# RZT2H register map
Vendor: Renesas Electronics Corporation; Series: RZT; File version: 1.00.00
CPU: other r0p0, little endian, MPU, no FPU, VTOR, 4 interrupt priority bits, 624 interrupts
Registers are 32-bit, read-write, reset 0x0 unless marked. A register's access mark holds for its fields unless they carry their own. Offsets are from the block's base; [hi:lo] are bit positions; {n}, {i} and the like mark numbered series.

## MSAC — Master and Slave Access Control
Base 0x81290300
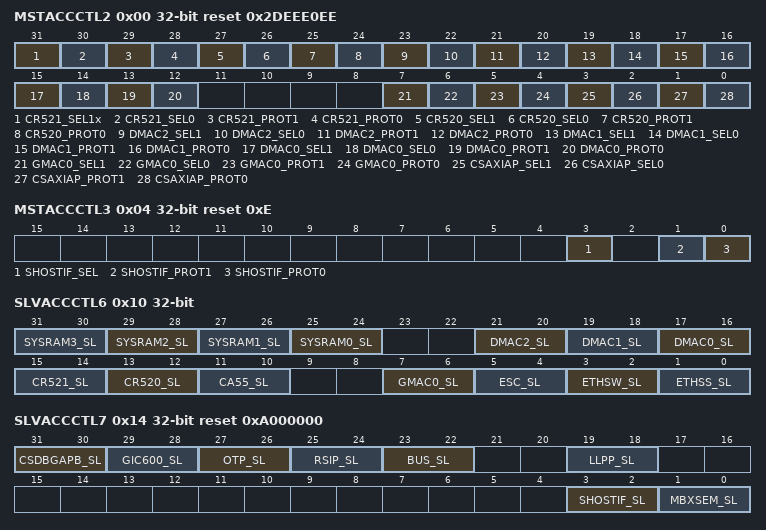
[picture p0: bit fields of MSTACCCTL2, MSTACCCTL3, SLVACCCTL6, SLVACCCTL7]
0x00 MSTACCCTL2 reset 0x2DEEE0EE — Master Access Control Register 2
  [31] CR521_SEL1x — CR521 Security Attribute (AxPROT[1]) Overwrite Select
    0=No overwrite; 1=Overwritten by CR521_PROT1
  [30] CR521_SEL0 — CR521 Privilege Attribute (AxPROT[0]) Overwrite Select
    0=No overwrite; 1=Overwritten by CR521_PROT0
  [29] CR521_PROT1 — CR521 Security Attribute Overwrite
    0=Secure; 1=Non-Secure
  [28] CR521_PROT0 — CR521 Privilege Attribute Overwrite
    0=Unprivileged; 1=Privileged
  [27] CR520_SEL1 — CR520 Security Attribute (AxPROT[1]) Overwrite Select
    0=No overwrite; 1=Overwritten by CR520_PROT1
  [26] CR520_SEL0 — CR520 Privilege Attribute (AxPROT[0]) Overwrite Select
    0=No overwrite; 1=Overwritten by CR520_PROT0
  [25] CR520_PROT1 — CR520 Security Attribute Overwrite
    0=Secure; 1=Non-Secure
  [24] CR520_PROT0 — CR520 Privilege Attribute Overwrite
    0=Unprivileged; 1=Privileged
  [23] DMAC2_SEL1 — DMAC2 Security Attribute (AxPROT[1]) Overwrite Select
    0=No overwrite; 1=Overwritten by DMAC2_PROT1
  [22] DMAC2_SEL0 — DMAC2 Privilege Attribute (AxPROT[0]) Overwrite Select
    0=No overwrite; 1=Overwritten by DMAC2_PROT0
  [21] DMAC2_PROT1 — DMAC2 Security Attribute Overwrite
    0=Secure; 1=Non-Secure
  [20] DMAC2_PROT0 — DMAC2 Privilege Attribute Overwrite
    0=Unprivileged; 1=Privileged
  [19] DMAC1_SEL1 — DMAC1 Security Attribute (AxPROT[1]) Overwrite Select
    0=No overwrite; 1=Overwritten by DMAC1_PROT1
  [18] DMAC1_SEL0 — DMAC1 Privilege Attribute (AxPROT[0]) Overwrite Select
    0=No overwrite; 1=Overwritten by DMAC1_PROT0
  [17] DMAC1_PROT1 — DMAC1 Security Attribute Overwrite
    0=Secure; 1=Non-Secure
  [16] DMAC1_PROT0 — DMAC1 Privilege Attribute Overwrite
    0=Unprivileged; 1=Privileged
  [15] DMAC0_SEL1 — DMAC0 Security Attribute (AxPROT[1]) Overwrite Select
    0=No overwrite; 1=Overwritten by DMAC0_PROT1
  [14] DMAC0_SEL0 — DMAC0 Privilege Attribute (AxPROT[0]) Overwrite Select
    0=No overwrite; 1=Overwritten by DMAC0_PROT0
  [13] DMAC0_PROT1 — DMAC0 Security Attribute Overwrite
    0=Secure; 1=Non-Secure
  [12] DMAC0_PROT0 — DMAC0 Privilege Attribute Overwrite
    0=Unprivileged; 1=Privileged
  [7] GMAC0_SEL1 — GMAC0 Security Attribute (AxPROT[1]) Overwrite Select
    0=No overwrite; 1=Overwritten by GMAC0_PROT1
  [6] GMAC0_SEL0 — GMAC0 Privilege Attribute (AxPROT[0]) Overwrite Select
    0=No overwrite; 1=Overwritten by GMAC0_PROT0
  [5] GMAC0_PROT1 — GMAC0 Security Attribute Overwrite
    0=Secure; 1=Non-Secure
  [4] GMAC0_PROT0 — GMAC0 Privilege Attribute Overwrite
    0=Unprivileged; 1=Privileged
  [3] CSAXIAP_SEL1 — CS AXI-AP Security Attribute (AxPROT[1]) Overwrite Select
    0=No overwrite; 1=Overwritten by CSAXIAP_PROT1
  [2] CSAXIAP_SEL0 — CS AXI-AP Privilege Attribute (AxPROT[0]) Overwrite Select
    0=No overwrite; 1=Overwritten by CSAXIAP_PROT0
  [1] CSAXIAP_PROT1 — CS AXI-AP Security Attribute Overwrite
    0=Secure; 1=Non-Secure
  [0] CSAXIAP_PROT0 — CS AXI-AP Privilege Attribute Overwrite
    0=Unprivileged; 1=Privileged
0x04 MSTACCCTL3 reset 0xE — Master Access Control Register 3
  [3] SHOSTIF_SEL — SHOSTIF Security Attribute (HNONSEC) and Privilege Attribute (HPROT[1]) Overwrite Select
    0=No overwrite; 1=Overwritten by SHOSTIF_PROT[1:0]
  [1] SHOSTIF_PROT1 — SHOSTIF Security Attribute Overwrite
    0=Secure; 1=Non-Secure
  [0] SHOSTIF_PROT0 — SHOSTIF Privilege Attribute Overwrite
    0=Unprivileged; 1=Privileged
0x10 SLVACCCTL6 — Slave Access Control Register 6
  [2n+25:2n+24] SYSRAM{n}_SL (n=0..3), [21:20] DMAC2_SL, [19:18] DMAC1_SL, [17:16] DMAC0_SL, [15:14] CR521_SL, [13:12] CR520_SL, [11:10] CA55_SL, [7:6] GMAC0_SL, [5:4] ESC_SL, [3:2] ETHSW_SL, [1:0] ETHSS_SL
0x14 SLVACCCTL7 reset 0xA000000 — Slave Access Control Register 7
  [31:30] CSDBGAPB_SL
  [29:28] GIC600_SL
  [27:26] OTP_SL
  [25:24] RSIP_SL
  [23:22] BUS_SL — Bus Security Level
  [19:18] LLPP_SL
  [3:2] SHOSTIF_SL
  [1:0] MBXSEM_SL
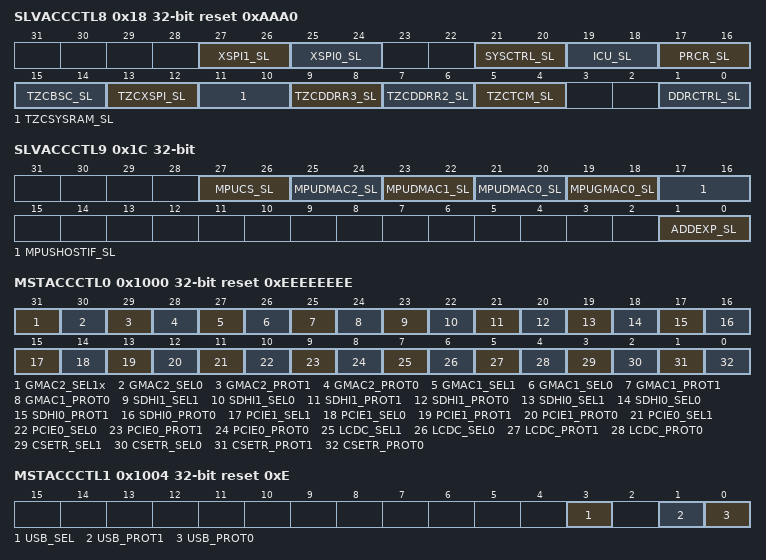
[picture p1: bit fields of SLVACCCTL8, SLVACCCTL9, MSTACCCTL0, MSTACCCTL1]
0x18 SLVACCCTL8 reset 0xAAA0 — Slave Access Control Register 8
  [27:26] XSPI1_SL, [25:24] XSPI0_SL, [21:20] SYSCTRL_SL, [19:18] ICU_SL, [17:16] PRCR_SL, [15:14] TZCBSC_SL, [13:12] TZCXSPI_SL, [11:10] TZCSYSRAM_SL, [9:8] TZCDDRR3_SL, [7:6] TZCDDRR2_SL, [5:4] TZCTCM_SL, [1:0] DDRCTRL_SL
0x1C SLVACCCTL9 — Slave Access Control Register 9
  [27:26] MPUCS_SL, [25:24] MPUDMAC2_SL, [23:22] MPUDMAC1_SL, [21:20] MPUDMAC0_SL, [19:18] MPUGMAC0_SL, [17:16] MPUSHOSTIF_SL, [1:0] ADDEXP_SL
0x1000 MSTACCCTL0 reset 0xEEEEEEEE — Master Access Control Register 0
  [31] GMAC2_SEL1x
    0=No overwrite; 1=Overwritten by GMAC2_PROT1
  [30] GMAC2_SEL0
    0=No overwrite; 1=Overwritten by GMAC2_PROT0
  [29] GMAC2_PROT1
    0=Secure; 1=Non-Secure
  [28] GMAC2_PROT0
    0=Unprivileged; 1=Privileged
  [27] GMAC1_SEL1
    0=No overwrite; 1=Overwritten by GMAC1_PROT1
  [26] GMAC1_SEL0
    0=No overwrite; 1=Overwritten by GMAC1_PROT0
  [25] GMAC1_PROT1
    0=Secure; 1=Non-Secure
  [24] GMAC1_PROT0
    0=Unprivileged; 1=Privileged
  [23] SDHI1_SEL1
    0=No overwrite; 1=Overwritten by SDHI1_PROT1
  [22] SDHI1_SEL0
    0=No overwrite; 1=Overwritten by SDHI1_PROT0
  [21] SDHI1_PROT1
    0=Secure; 1=Non-Secure
  [20] SDHI1_PROT0
    0=Unprivileged; 1=Privileged
  [19] SDHI0_SEL1
    0=No overwrite; 1=Overwritten by SDHI0_PROT1
  [18] SDHI0_SEL0
    0=No overwrite; 1=Overwritten by SDHI0_PROT0
  [17] SDHI0_PROT1
    0=Secure; 1=Non-Secure
  [16] SDHI0_PROT0
    0=Unprivileged; 1=Privileged
  [15] PCIE1_SEL1
    0=No overwrite; 1=Overwritten by PCIE1_PROT1
  [14] PCIE1_SEL0
    0=No overwrite; 1=Overwritten by PCIE1_PROT0
  [13] PCIE1_PROT1
    0=Secure; 1=Non-Secure
  [12] PCIE1_PROT0
    0=Unprivileged; 1=Privileged
  [11] PCIE0_SEL1
    0=No overwrite; 1=Overwritten by PCIE0_PROT1
  [10] PCIE0_SEL0
    0=No overwrite; 1=Overwritten by PCIE0_PROT0
  [9] PCIE0_PROT1
    0=Secure; 1=Non-Secure
  [8] PCIE0_PROT0
    0=Unprivileged; 1=Privileged
  [7] LCDC_SEL1
    0=No overwrite; 1=Overwritten by LCDC_PROT1
  [6] LCDC_SEL0
    0=No overwrite; 1=Overwritten by LCDC_PROT0
  [5] LCDC_PROT1
    0=Secure; 1=Non-Secure
  [4] LCDC_PROT0
    0=Unprivileged; 1=Privileged
  [3] CSETR_SEL1
    0=No overwrite; 1=Overwritten by CSETR_PROT1
  [2] CSETR_SEL0
    0=No overwrite; 1=Overwritten by CSETR_PROT0
  [1] CSETR_PROT1
    0=Secure; 1=Non-Secure
  [0] CSETR_PROT0
    0=Unprivileged; 1=Privileged
0x1004 MSTACCCTL1 reset 0xE — Master Access Control Register 1
  [3] USB_SEL
    0=No overwrite; 1=Overwritten by USB_PROT[1:0]
  [1] USB_PROT1
    0=Secure; 1=Non-Secure
  [0] USB_PROT0
    0=Unprivileged; 1=Privileged
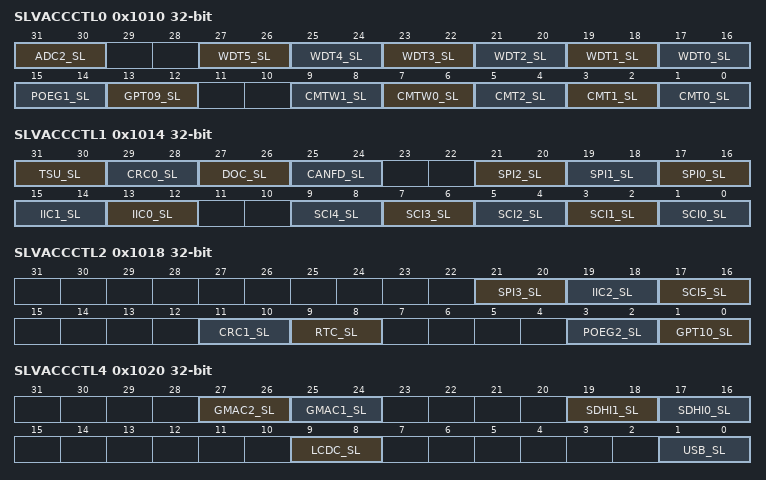
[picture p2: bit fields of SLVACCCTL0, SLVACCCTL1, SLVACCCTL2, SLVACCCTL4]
0x1010 SLVACCCTL0 — Slave Access Control Register 0
  [31:30] ADC2_SL, [2n+17:2n+16] WDT{n}_SL (n=0..5), [15:14] POEG1_SL, [13:12] GPT09_SL, [9:8] CMTW1_SL, [7:6] CMTW0_SL, [5:4] CMT2_SL, [3:2] CMT1_SL, [1:0] CMT0_SL
0x1014 SLVACCCTL1 — Slave Access Control Register 1
  [31:30] TSU_SL, [29:28] CRC0_SL, [27:26] DOC_SL, [25:24] CANFD_SL, [21:20] SPI2_SL, [19:18] SPI1_SL, [17:16] SPI0_SL, [15:14] IIC1_SL, [13:12] IIC0_SL, [2n+1:2n] SCI{n}_SL (n=0..4)
0x1018 SLVACCCTL2 — Slave Access Control Register 2
  [21:20] SPI3_SL, [19:18] IIC2_SL, [17:16] SCI5_SL, [11:10] CRC1_SL, [9:8] RTC_SL, [3:2] POEG2_SL, [1:0] GPT10_SL
0x1020 SLVACCCTL4 — Slave Access Control Register 4
  [27:26] GMAC2_SL, [25:24] GMAC1_SL, [19:18] SDHI1_SL, [17:16] SDHI0_SL, [9:8] LCDC_SL, [1:0] USB_SL
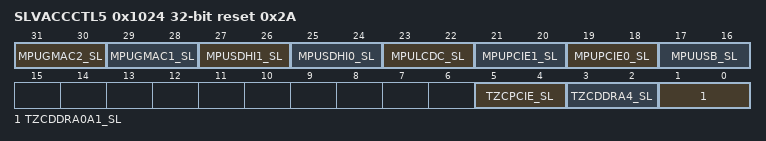
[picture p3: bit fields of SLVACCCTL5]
0x1024 SLVACCCTL5 reset 0x2A — Slave Access Control Register 5
  [31:30] MPUGMAC2_SL, [29:28] MPUGMAC1_SL, [27:26] MPUSDHI1_SL, [25:24] MPUSDHI0_SL, [23:22] MPULCDC_SL, [21:20] MPUPCIE1_SL, [19:18] MPUPCIE0_SL, [17:16] MPUUSB_SL, [5:4] TZCPCIE_SL, [3:2] TZCDDRA4_SL, [1:0] TZCDDRA0A1_SL
